# SIM3U167_B register map
File version: 1
CPU: 
Registers are 32-bit, read-write, reset 0x0 unless marked. A register's access mark holds for its fields unless they carry their own. Offsets are from the block's base; [hi:lo] are bit positions; 'fields as' and 'values as' point back to an identical list.

## I2S_0
Base 0x4003A000
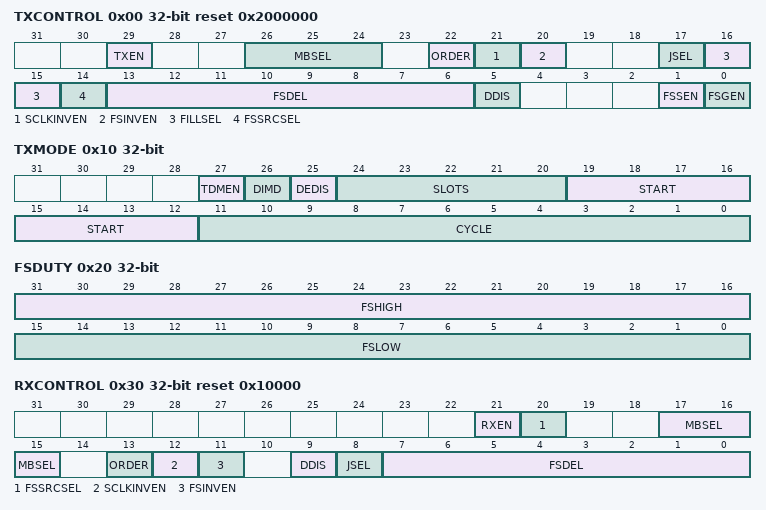
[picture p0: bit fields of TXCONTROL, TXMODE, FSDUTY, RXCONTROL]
0x00 TXCONTROL reset 0x2000000 — Transmit Control
  [29] TXEN — Transmitter Enable.
    0=DISABLED (Disable the I2S transmitter.); 1=ENABLED (Enable the I2S transmitter.)
  [26:24] MBSEL — Transmit Mono Bit-Width Select.
    0=8BITS (8 bits are sent per mono sample.); 1=9BITS (9 bits are sent per mono sample.); 2=16BITS (16 bits are sent per mono sample.); 3=24BITS (24 bits are sent per mono sample.); 4=32BITS (32 bits are sent per mono sample.)
  [22] ORDER — Transmit Order.
    0=LEFT_RIGHT (Left sample transmitted first, right sample transmitted second. Use this setting for I2S format.); 1=RIGHT_LEFT (Right sample transmitted first, left sample transmitted second.)
  [21] SCLKINVEN — Transmit SCK Inversion Enable.
    0=DISABLED (Do not invert the transmitter bit clock.); 1=ENABLED (Invert the transmitter bit clock.)
  [20] FSINVEN — Transmit WS Inversion Enable.
    0=DISABLED (Don't invert the WS signal. Use this setting for I2S format.); 1=ENABLED (Invert the WS signal.)
  [17] JSEL — Transmit Data Justification Select.
    0=LEFT (Use left-justified or I2S-style formats.); 1=RIGHT (Use right-justified format.)
  [16:15] FILLSEL — Transmit Data Fill Select.
    0=ZEROS (Send zeros during unused bit cycles.); 1=ONES (Send ones during unused bit cycles.); 2=SIGN (Send the sign bit of the current sample (MSB-first format) or last sample (LSB-first format) during unused bit cycles.); 3=RANDOM (Send pseudo-random data generated by an 8-bit LFSR during unused bit cycles.)
  [14] FSSRCSEL — Transmit Frame Sync Source Select.
    0=FSIN_EXT (The word select or frame sync is input from the WS pin.); 1=FSIN_INT (The word select or frame sync is input from the internal DFS generator.)
  [13:6] FSDEL — Transmit Initial Phase Delay.
  [5] DDIS — Transmit Delay Disable.
    0=INACTIVE (The first data bit is sent on the second or later rising edge of SCK after WS changes.); 1=ACTIVE (The first data bit is sent on the first rising edge of SCK after WS changes.)
  [1] FSSEN — DFS Synchronize Enable.
    0=DISABLED (The internal DFS generator starts immediately when FSGEN is set to 1.); 1=ENABLED (Synchronize the rising edge of the internally generated WS signal from the DFS generator to the rising edge of the external WS input signal.)
  [0] FSGEN — DFS Generator Enable.
    0=DISABLED (Disable the internal DFS generator.); 1=ENABLED (Enable the internal DFS generator.)
0x10 TXMODE — Transmit Mode
  [27] TDMEN — Transmit Time Division Multiplexing Enable.
    0=DISABLED (Disable the time division multiplexing (TDM) feature.); 1=ENABLED (Enable the time division multiplexing (TDM) feature.)
  [26] DIMD — Transmit Drive Inactive Mode.
    0=ZERO (Drive zero on the data output pin during non-active slots.); 1=HIGH_Z (Don't drive the data output pin. The data output pin is tristated.)
  [25] DEDIS — Transmit Drive Early Disable.
    0=INACTIVE (Drive the output during every cycle of the transmitter's assigned slot(s), including the last clock cycle.); 1=ACTIVE (Drive the output for every cycle of the transmitter's assigned slot(s), except for the last clock cycle of the last slot.)
  [24:20] SLOTS — Transmit Drive Select.
  [19:12] START — Transmit Start Control.
  [11:0] CYCLE — Transmit Clock Cycle Select.
0x20 FSDUTY — Frame Sync Duty Cycle
  [31:16] FSHIGH — Frame Sync High Time.
  [15:0] FSLOW — Frame Sync Low Time.
0x30 RXCONTROL reset 0x10000 — Receive Control
  [21] RXEN — Receive Enable.
    0=DISABLED (Disable the I2S receiver.); 1=ENABLED (Enable the I2S receiver.)
  [20] FSSRCSEL — Receive Frame Sync Source Select.
    values as TXCONTROL.FSSRCSEL
  [17:15] MBSEL — Receive Mono Bit-Width Select.
    0=8BITS (8 bits are received per mono sample.); 1=9BITS (9 bits are received per mono sample.); 2=16BITS (16 bits are received per mono sample.); 3=24BITS (24 bits are received per mono sample.); 4=32BITS (32 bits are received per mono sample.)
  [13] ORDER — Receive Order.
    0=LEFT_RIGHT (Left sample received first, right sample received second. Use this setting for I2S format.); 1=RIGHT_LEFT (Right sample received first, left sample received second.)
  [12] SCLKINVEN — Receive SCK Inversion Enable.
    0=DISABLED (Do not invert the receiver bit clock.); 1=ENABLED (Invert the receiver bit clock.)
  [11] FSINVEN — Receive WS Inversion Enable.
    values as TXCONTROL.FSINVEN
  [9] DDIS — Receive Delay Disable.
    0=INACTIVE (The first data bit is captured on the second or later rising edge of SCK after WS changes.); 1=ACTIVE (The first data bit is captured by the receiver on the first rising edge of SCK after WS changes.)
  [8] JSEL — Receive Data Justification.
    values as TXCONTROL.JSEL
  [7:0] FSDEL — Receive Initial Phase Delay.
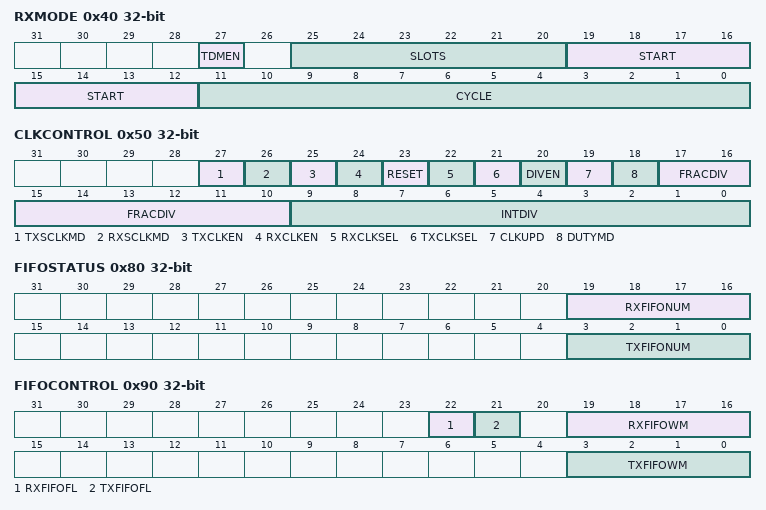
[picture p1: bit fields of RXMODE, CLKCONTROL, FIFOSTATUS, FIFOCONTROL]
0x40 RXMODE — Receive Mode
  [27] TDMEN — Receive Time Division Multiplexing Enable.
    values as TXMODE.TDMEN
  [25:20] SLOTS — Receive Drive Select.
  [19:12] START — Receive Start Control.
  [11:0] CYCLE — Receive Clock Cycle Select.
0x50 CLKCONTROL — Clock Control
  [27] TXSCLKMD — Transmit SCK Mode.
    0=SCK_OUTPUT (The I2S transmitter SCK signal is an output.); 1=SCK_INPUT (The I2S transmitter SCK signal is an input.)
  [26] RXSCLKMD — Receive SCK Mode.
    0=SCK_OUTPUT (The I2S receiver SCK signal is an output.); 1=SCK_INPUT (The I2S receiver SCK signal is an input.)
  [25] TXCLKEN — Transmit Clock Enable.
    0=DISABLED (Disable the I2S transmitter clock.); 1=ENABLED (Enable the I2S transmitter clock.)
  [24] RXCLKEN — Receive Clock Enable.
    0=DISABLED (Disable the I2S receiver clock.); 1=ENABLED (Enable the I2S receiver clock.)
  [23] RESET wo — I2S Module Reset.
    1=ACTIVE (Reset the I2S module.)
  [22] RXCLKSEL — Receive Clock Select.
    0=INTERNAL (The I2S receiver is clocked from the internal clock divider.); 1=EXTERNAL (The I2S receiver is clocked from the SCK pin.)
  [21] TXCLKSEL — Transmit Clock Select.
    0=INTERNAL (The I2S transmitter is clocked from the internal clock divider.); 1=EXTERNAL (The I2S transmitter is clocked from the SCK pin.)
  [20] DIVEN — Clock Divider Enable.
    0=DISABLED (Disable the clock divider.); 1=ENABLED (Enable the clock divider.)
  [19] CLKUPD wo — Clock Divider Update.
    1=UPDATE (Update the clock divider with new values of INTDIV, FRACDIV, and DIVEN.)
  [18] DUTYMD — Duty Cycle Adjustment Mode.
    0=MORE (When the division is fractional, the clock high time will be greater than 50% (by half of the source clock period).); 1=LESS (When the division is fractional, the clock low time will be greater than 50% (by half of the source clock period).)
  [17:10] FRACDIV — Clock Divider Fractional Value.
  [9:0] INTDIV — Clock Divider Integer Value.
0x60 TXFIFO read-has-side-effects — Transmit Data FIFO
  [31:0] TXFIFO wo — Transmit Data FIFO.
0x70 RXFIFO read-has-side-effects — Receive Data FIFO
  [31:0] RXFIFO ro — Receive Data FIFO.
0x80 FIFOSTATUS
  [19:16] RXFIFONUM ro — Receive FIFO Status.
  [3:0] TXFIFONUM ro — Transmit FIFO Status.
0x90 FIFOCONTROL
  [22] RXFIFOFL wo — Receive FIFO Flush.
    1=SET (Flush the I2S receiver FIFO.)
  [21] TXFIFOFL wo — Transmit FIFO Flush.
    1=SET (Flush the I2S transmitter FIFO.)
  [19:16] RXFIFOWM — Receive FIFO High Watermark.
  [3:0] TXFIFOWM — Transmit FIFO Low Watermark.
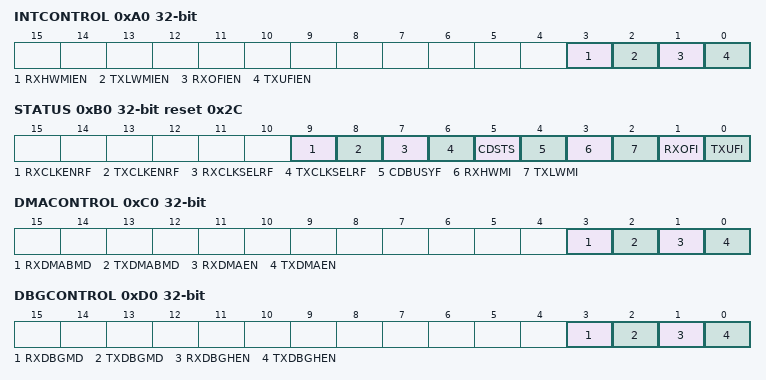
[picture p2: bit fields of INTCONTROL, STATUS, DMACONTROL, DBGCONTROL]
0xA0 INTCONTROL — Interrupt Control
  [3] RXHWMIEN — Receive FIFO High Watermark Interrupt Enable.
    0=DISABLED (Disable the receive FIFO high watermark interrupt.); 1=ENABLED (Enable the receive FIFO high watermark interrupt.)
  [2] TXLWMIEN — Transmit FIFO Low Watermark Interrupt Enable.
    0=DISABLED (Disable the transmit FIFO low watermark interrupt.); 1=ENABLED (Enable the transmit FIFO low watermark interrupt.)
  [1] RXOFIEN — Receive Overflow Interrupt Enable.
    0=DISABLED (Disable the receive overflow interrupt.); 1=ENABLED (Enable the receive overflow interrupt.)
  [0] TXUFIEN — Transmit Underflow Interrupt Enable.
    0=DISABLED (Disable the transmit underflow interrupt.); 1=ENABLED (Enable the transmit underflow interrupt.)
0xB0 STATUS reset 0x2C — Module Status
  [9] RXCLKENRF ro — Receive Clock Enable Ready Flag.
    0=NOT_SET (The receive clock is not synchronized.); 1=SET (The receive clock is synchronized and the receiver is ready to accept data.)
  [8] TXCLKENRF ro — Transmit Clock Enable Ready Flag.
    0=NOT_SET (The transmit clock is not synchronized.); 1=SET (The transmit clock is synchronized and the transmitter is ready to send data.)
  [7] RXCLKSELRF ro — Receive Clock Select Ready Flag.
    values as RXCLKENRF
  [6] TXCLKSELRF ro — Transmit Clock Select Ready Flag.
    values as TXCLKENRF
  [5] CDSTS ro — Clock Divider Counter Status.
    0=RUNNING (Divided clock output is running.); 1=HALTED (Divided clock output is halted.)
  [4] CDBUSYF ro — Clock Divider Busy Flag.
    0=NOT_BUSY (The divider is not busy and an update is not pending.); 1=BUSY (The divider is busy and an update is pending.)
  [3] RXHWMI ro — Receive FIFO High Watermark Interrupt Flag.
    0=NOT_SET (Receive FIFO level is below the high watermark.); 1=SET (Receive FIFO level is at or above the high watermark.)
  [2] TXLWMI ro — Transmit FIFO Low Watermark Interrupt Flag.
    0=NOT_SET (Transmit FIFO level is above the low watermark.); 1=SET (Transmit FIFO level is at or below the low watermark.)
  [1] RXOFI — Receive Overflow Interrupt Flag.
    0=NOT_SET (A receive overflow has not occurred.); 1=SET (A receive overflow occurred.)
  [0] TXUFI — Transmit Underflow Interrupt Flag.
    0=NOT_SET (A transmit underflow has not occurred.); 1=SET (A transmit underflow occurred.)
0xC0 DMACONTROL
  [3] RXDMABMD — Receive DMA Burst Mode.
    0=ONE_WORD (The receiver receives one word at a time. Whenever there is at least one word in the receive FIFO, a single word burst DMA request is generated.); 1=FOUR_WORDS (The receiver receives four words at a time. Whenever the FIFO depth rises above three, a DMA burst request is generated for four words.)
  [2] TXDMABMD — Transmit DMA Burst Mode.
    0=ONE_WORD (The transmitter transmits one word at a time. Whenever there is any room in the transmit FIFO, a single word burst DMA data request is generated.); 1=FOUR_WORDS (The transmitter transmits four words at a time. Whenever the FIFO depth drops below five, a DMA burst request is generated for four words.)
  [1] RXDMAEN — Receive DMA Enable.
    0=DISABLED (Disable receiver DMA data transfer requests.); 1=ENABLED (Enable receiver DMA data transfer requests.)
  [0] TXDMAEN — Transmit DMA Enable.
    0=DISABLED (Disable transmitter DMA data requests.); 1=ENABLED (Enable transmitter DMA data requests.)
0xD0 DBGCONTROL — Debug Control
  [3] RXDBGMD — I2S Receive Debug Mode.
    0=RUN (The clock to the I2S receiver is active in debug mode.); 1=HALT (The clock to the I2S receiver is not active in debug mode. The clock divider keeps running and the clock will be disabled when two samples are captured in the receiver.)
  [2] TXDBGMD — I2S Transmit Debug Mode.
    0=RUN (The clock to the I2S transmitter is active in debug mode.); 1=HALT (The clock to the I2S transmitter is not active in debug mode. The clock divider keeps running and the clock will be disabled when two samples are ready to be sent by the transmitter.)
  [1] RXDBGHEN — I2S Receive DMA Debug Halt Enable.
    0=DISABLED (Receive DMA requests continue while the core is debug mode.); 1=ENABLED (Receive DMA requests stop while the core is debug mode.)
  [0] TXDBGHEN — I2S Transmit DMA Debug Halt Enable.
    0=DISABLED (Transmit DMA requests continue while the core is debug mode.); 1=ENABLED (Transmit DMA requests stop while the core is debug mode.)
